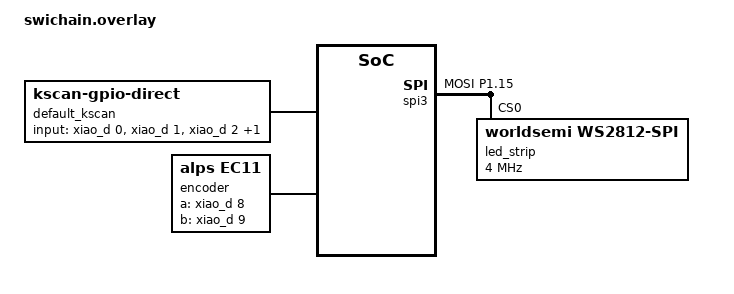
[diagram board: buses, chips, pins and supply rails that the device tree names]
/ {
    chosen {
        zmk,kscan = &default_kscan;
    };
 
    default_kscan: kscan {
        compatible = "zmk,kscan-gpio-direct";
        label = "default_kscan";
 
        input-gpios =
            <&xiao_d 0 (GPIO_ACTIVE_HIGH | GPIO_PULL_UP)>,
            <&xiao_d 1 (GPIO_ACTIVE_HIGH | GPIO_PULL_UP)>,
            <&xiao_d 2 (GPIO_ACTIVE_HIGH | GPIO_PULL_UP)>,
            <&xiao_d 3 (GPIO_ACTIVE_HIGH | GPIO_PULL_UP)>;
            <&xiao_d 4 (GPIO_ACTIVE_HIGH | GPIO_PULL_UP)>,
            <&xiao_d 5 (GPIO_ACTIVE_HIGH | GPIO_PULL_UP)>,
            <&xiao_d 6 (GPIO_ACTIVE_HIGH | GPIO_PULL_UP)>,
            <&xiao_d 7 (GPIO_ACTIVE_HIGH | GPIO_PULL_UP)>;
    };
 
    left_encoder: encoder_left {
        compatible = "alps,ec11";
        label = "encoder";
        a-gpios = <&xiao_d 8 (GPIO_ACTIVE_HIGH | GPIO_PULL_UP)>;
        b-gpios = <&xiao_d 9 (GPIO_ACTIVE_HIGH | GPIO_PULL_UP)>;
        steps = <80>;
        status = "okay";
    };
 
    sensors {
        compatible = "zmk,keymap-sensors";
        sensors = <&left_encoder>;
    };
};

#include <dt-bindings/led/led.h>

&pinctrl {
    spi3_default: spi3_default {
        group1 {
            psels = <NRF_PSEL(SPIM_MOSI, 1, 15)>;
        };
    };

    spi3_sleep: spi3_sleep {
        group1 {
            psels = <NRF_PSEL(SPIM_MOSI, 1, 15)>;
            low-power-enable;
        };
    };
};

&spi3 {
    compatible = "nordic,nrf-spim";
    status = "okay";

    pinctrl-0 = <&spi3_default>;
    pinctrl-1 = <&spi3_sleep>;
    pinctrl-names = "default", "sleep";

    led_strip: ws2812@0 {
        compatible = "worldsemi,ws2812-spi";

        /* SPI */
        reg = <0>; /* ignored, but necessary for SPI bindings */
        spi-max-frequency = <4000000>;

        /* WS2812 */
        chain-length = <6>; /* number of LEDs */
        spi-one-frame = <0x70>;
        spi-zero-frame = <0x40>;
        color-mapping = <LED_COLOR_ID_GREEN
                         LED_COLOR_ID_RED
                         LED_COLOR_ID_BLUE>;
    };
};
